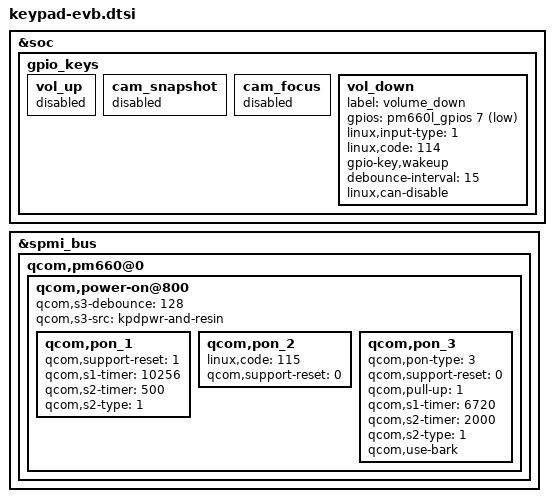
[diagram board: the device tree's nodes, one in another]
&soc {
	gpio_keys {

		vol_up {
			status = "disabled";
		};

		cam_snapshot {
			status = "disabled";
		};

		cam_focus {
			status = "disabled";
		};

		vol_down {
			label = "volume_down";
			gpios = <&pm660l_gpios 7 GPIO_ACTIVE_LOW>;
			linux,input-type = <1>;
			linux,code = <114>;
			gpio-key,wakeup;
			debounce-interval = <15>;
			linux,can-disable;
		};
	};
};

&spmi_bus {
  qcom,pm660@0 {
		qcom,power-on@800 {
			qcom,s3-debounce = <128>;
			qcom,s3-src = "kpdpwr-and-resin";
			/* PON: KPDPWR */
			qcom,pon_1 {
				qcom,support-reset = <1>;
				/* RESET TRIGGER TIME: S1 + S2 = 10756ms */
				qcom,s1-timer = <10256>;
				qcom,s2-timer = <500>;
				/* RESET TYPE: SHUTDOWN(4) */
				qcom,s2-type = <1>;
			};

			/* PON: RESIN */
			qcom,pon_2 {
				linux,code = <115>;
				qcom,support-reset = <0>;
			};

			qcom,pon_3 {
				qcom,pon-type = <3>;
				qcom,support-reset = <0>;
				qcom,pull-up = <1>;
				/* RESET TRIGGER TIME: S1 + S2 = 8720ms */
				qcom,s1-timer = <6720>;
				qcom,s2-timer = <2000>;
				/* RESET TYPE: WARM(1) */
				qcom,s2-type = <1>;
				qcom,use-bark;
			};
		};
	};
};
